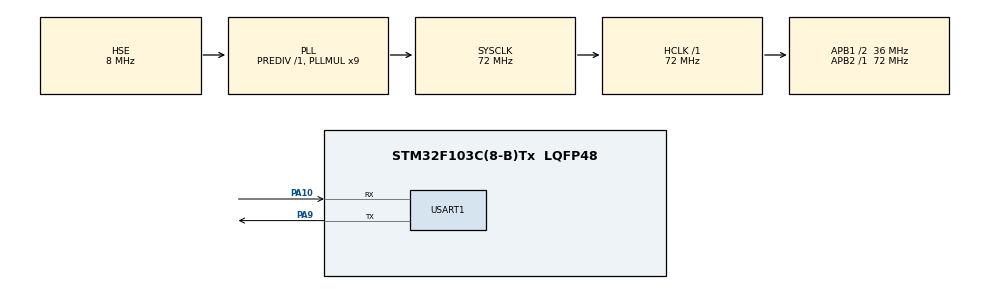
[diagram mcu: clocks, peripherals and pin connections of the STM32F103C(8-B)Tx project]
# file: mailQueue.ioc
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FREERTOS.Queues01=myQueue01,16,uint16_t,0,Dynamic,NULL,NULL
FREERTOS.Tasks01=myTask01,0,128,StartDefaultTask,Default,NULL,Dynamic,NULL,NULL;myTask02,0,128,StartTask02,Default,NULL,Dynamic,NULL,NULL
Mcu.Family=STM32F1
Mcu.Name=STM32F103C(8-B)Tx
Mcu.Package=LQFP48
NVIC.PriorityGroup=NVIC_PRIORITYGROUP_4
NVIC.TIM4_IRQn=true\:15\:0\:false\:false\:true\:false\:false\:true\:true
NVIC.TimeBase=TIM4_IRQn
NVIC.TimeBaseIP=TIM4
PA10.Mode=Asynchronous
PA10.Signal=USART1_RX
PA13.Mode=Serial_Wire
PA13.Signal=SYS_JTMS-SWDIO
PA14.Mode=Serial_Wire
PA14.Signal=SYS_JTCK-SWCLK
PA9.Mode=Asynchronous
PA9.Signal=USART1_TX
PD0-OSC_IN.Mode=HSE-External-Oscillator
PD0-OSC_IN.Signal=RCC_OSC_IN
PD1-OSC_OUT.Mode=HSE-External-Oscillator
PD1-OSC_OUT.Signal=RCC_OSC_OUT
ProjectManager.HeapSize=0x200
ProjectManager.StackSize=0x400
ProjectManager.TargetToolchain=STM32CubeIDE
RCC.AHBFreq_Value=72000000
RCC.APB1CLKDivider=RCC_HCLK_DIV2
RCC.APB1Freq_Value=36000000
RCC.APB1TimFreq_Value=72000000
RCC.APB2Freq_Value=72000000
RCC.APB2TimFreq_Value=72000000
RCC.HCLKFreq_Value=72000000
RCC.PLLMUL=RCC_PLL_MUL9
RCC.PLLSourceVirtual=RCC_PLLSOURCE_HSE
RCC.SYSCLKFreq_VALUE=72000000
RCC.SYSCLKSource=RCC_SYSCLKSOURCE_PLLCLK
RCC.USBFreq_Value=72000000
USART1.VirtualMode=VM_ASYNC
VP_FREERTOS_VS_CMSIS_V1.Mode=CMSIS_V1
VP_SYS_VS_tim4.Mode=TIM4
board=custom

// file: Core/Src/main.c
/* USER CODE BEGIN Header */
/**
  ******************************************************************************
  * @file           : main.c
  * @brief          : Main program body
  ******************************************************************************
  * @attention
  *
  * Copyright (c) 2025 STMicroelectronics.
  * All rights reserved.
  *
  * This software is licensed under terms that can be found in the LICENSE file
  * in the root directory of this software component.
  * If no LICENSE file comes with this software, it is provided AS-IS.
  *
  ******************************************************************************
  */
/* USER CODE END Header */
#include "main.h"
#include "cmsis_os.h"

UART_HandleTypeDef huart1;

osThreadId myTask01Handle;
osThreadId myTask02Handle;
//osMessageQId myQueue01Handle;
osMailQId myQueue01Handle;
/* USER CODE BEGIN PV */
typedef struct {
	uint16_t xAccel;
	uint16_t yAccel;
	uint16_t zAccel;
} tDataStruct;

//typedef struct tDataStruct
/* USER CODE END PV */

void SystemClock_Config(void);
static void MX_GPIO_Init(void);
static void MX_USART1_UART_Init(void);
void StartDefaultTask(void const * argument);
void StartTask02(void const * argument);
void RxNoti(UART_HandleTypeDef *huart, tDataStruct *data);

int main(void)
{

  /* MCU Configuration--------------------------------------------------------*/

  /* Reset of all peripherals, Initializes the Flash interface and the Systick. */
  HAL_Init();

  /* Configure the system clock */
  SystemClock_Config();

  /* Initialize all configured peripherals */
  MX_GPIO_Init();
  MX_USART1_UART_Init();

  /* Create the queue(s) */
  /* definition and creation of myQueue01 */
//  osMessageQDef(myQueue01, 16, uint16_t);
//  myQueue01Handle = osMessageCreate(osMessageQ(myQueue01), NULL);
  osMailQDef(myQueue01, 16, tDataStruct);
  myQueue01Handle = osMailCreate(osMailQ(myQueue01), NULL);

  /* Create the thread(s) */
  /* definition and creation of myTask01 */
  osThreadDef(myTask01, StartDefaultTask, 3, 0, 128);
  myTask01Handle = osThreadCreate(osThread(myTask01), NULL);

  /* definition and creation of myTask02 */
//  osThreadDef(myTask02, StartTask02, 2, 0, 128);
  osThreadDef(myTask02, StartTask02, 2, 0, 256);
  myTask02Handle = osThreadCreate(osThread(myTask02), NULL);

  /* Start scheduler */
  osKernelStart();

  /* We should never get here as control is now taken by the scheduler */

  /* Infinite loop */
  while (1)
  {

  }
}

void SystemClock_Config(void)
{
  RCC_OscInitTypeDef RCC_OscInitStruct = {0};
  RCC_ClkInitTypeDef RCC_ClkInitStruct = {0};

  /** Initializes the RCC Oscillators according to the specified parameters
  * in the RCC_OscInitTypeDef structure.
  */
  RCC_OscInitStruct.OscillatorType = RCC_OSCILLATORTYPE_HSE;
  RCC_OscInitStruct.HSEState = RCC_HSE_ON;
  RCC_OscInitStruct.HSEPredivValue = RCC_HSE_PREDIV_DIV1;
  RCC_OscInitStruct.HSIState = RCC_HSI_ON;
  RCC_OscInitStruct.PLL.PLLState = RCC_PLL_ON;
  RCC_OscInitStruct.PLL.PLLSource = RCC_PLLSOURCE_HSE;
  RCC_OscInitStruct.PLL.PLLMUL = RCC_PLL_MUL9;
  if (HAL_RCC_OscConfig(&RCC_OscInitStruct) != HAL_OK)
  {
    Error_Handler();
  }

  /** Initializes the CPU, AHB and APB buses clocks
  */
  RCC_ClkInitStruct.ClockType = RCC_CLOCKTYPE_HCLK|RCC_CLOCKTYPE_SYSCLK
                              |RCC_CLOCKTYPE_PCLK1|RCC_CLOCKTYPE_PCLK2;
  RCC_ClkInitStruct.SYSCLKSource = RCC_SYSCLKSOURCE_PLLCLK;
  RCC_ClkInitStruct.AHBCLKDivider = RCC_SYSCLK_DIV1;
  RCC_ClkInitStruct.APB1CLKDivider = RCC_HCLK_DIV2;
  RCC_ClkInitStruct.APB2CLKDivider = RCC_HCLK_DIV1;

  if (HAL_RCC_ClockConfig(&RCC_ClkInitStruct, FLASH_LATENCY_2) != HAL_OK)
  {
    Error_Handler();
  }
}

static void MX_USART1_UART_Init(void)
{

  huart1.Instance = USART1;
  huart1.Init.BaudRate = 115200;
  huart1.Init.WordLength = UART_WORDLENGTH_8B;
  huart1.Init.StopBits = UART_STOPBITS_1;
  huart1.Init.Parity = UART_PARITY_NONE;
  huart1.Init.Mode = UART_MODE_TX_RX;
  huart1.Init.HwFlowCtl = UART_HWCONTROL_NONE;
  huart1.Init.OverSampling = UART_OVERSAMPLING_16;
  if (HAL_UART_Init(&huart1) != HAL_OK)
  {
    Error_Handler();
  }

}

static void MX_GPIO_Init(void)
{

  /* GPIO Ports Clock Enable */
  __HAL_RCC_GPIOD_CLK_ENABLE();
  __HAL_RCC_GPIOA_CLK_ENABLE();

}

/* USER CODE BEGIN 4 */
void RxNoti(UART_HandleTypeDef *huart, tDataStruct *data)
{
	  uint8_t rxBuff[120] = {};
	  uint8_t *notiStr = "Queue received a message: ";
	  snprintf((char*)rxBuff, sizeof(rxBuff), "Task02 is running\n% s%\n xAccel = %d\n yAccel = %d\n zAccel = %d\n", notiStr, data->xAccel, data->yAccel, data->zAccel);
	  HAL_UART_Transmit(&huart1, rxBuff, sizeof(rxBuff), 1000);
}
/* USER CODE END 4 */

uint8_t test = 0;
void StartDefaultTask(void const * argument)
{
  /* USER CODE BEGIN 5 */
//	  tDataStruct *txData = osMailAlloc(myQueue01Handle, 100);
//	  txData->xAccel = 1234;
//	  txData->yAccel = 5678;
//	  txData->zAccel = test++;
  /* Infinite loop */
  for(;;)
  {
	  tDataStruct *txData = osMailAlloc(myQueue01Handle, 100);
	  txData->xAccel = 1234;
	  txData->yAccel = 5678;
	  txData->zAccel = test++;
	  HAL_UART_Transmit(&huart1, "Task01 is running", sizeof ("Task01 is running"), 1000);
    osDelay(1000);
    osMailPut(myQueue01Handle, txData);
  }
  /* USER CODE END 5 */
}

tDataStruct *rxData;

void StartTask02(void const * argument)
{
  /* USER CODE BEGIN StartTask02 */
	osEvent rxEvent;
  /* Infinite loop */
  for(;;)
  {
	  rxEvent = osMailGet(myQueue01Handle, osWaitForever);
//	  rxEvent = osMailGet(myQueue01Handle, 5000);

	  if (rxEvent.status == osEventMail)
	  {
		  rxData = (tDataStruct*)rxEvent.value.p;
//		  RxNoti(&huart1, &rxData);
		  RxNoti(&huart1, rxData);
		  osMailFree(myQueue01Handle, rxData);
	  }
	  osDelay(100);
  }
  /* USER CODE END StartTask02 */
}

void HAL_TIM_PeriodElapsedCallback(TIM_HandleTypeDef *htim)
{
  if (htim->Instance == TIM4)
  {
    HAL_IncTick();
  }
}

void Error_Handler(void)
{
  __disable_irq();
  while (1)
  {
  }
}
